# CY8C4247LQI_BL483 register map
File version: 0.1
PSoC 4200 BLE
Registers are 8-bit, read-write, no defined reset value unless marked. A register's access mark holds for its fields unless they carry their own. Offsets are from the block's base; lines under a group give offsets from that group; [hi:lo] are bit positions; {n}, {i} and the like mark numbered series; 'fields as' and 'values as' point back to an identical list; <NAME> marks a mode.

## Memory map
0x00000000 PWM
0x400F0072 front_motor
0x400F0073 rear_motor

## PWM
Base 0x00000000
0x400F0021 PWM__COMPARE1 — UDB.D0 - Assigned Compare1 Value
0x400F0031 PWM__COMPARE2 — UDB.D1 - Assigned Compare2 Value
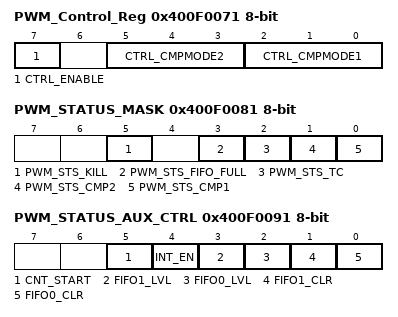
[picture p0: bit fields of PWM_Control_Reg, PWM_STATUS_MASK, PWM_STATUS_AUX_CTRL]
0x400F0071 PWM_Control_Reg — UDB Control Register - Assigned Control Register Value
  [7] CTRL_ENABLE — Enable the PWM
  [5:3] CTRL_CMPMODE2 — Compare mode 2
  [2:0] CTRL_CMPMODE1 — Compare mode 1
0x400F0081 PWM_STATUS_MASK — UDB Status bits Interrupt Mask Enable Register
  [5] PWM_STS_KILL ro — Enables the Interrupt on Kill
  [3] PWM_STS_FIFO_FULL ro — FIFO Full Status Mask
  [2] PWM_STS_TC ro — Enables the Interrupt on Terminal Count
  [1] PWM_STS_CMP2 ro — Enables the Interrupt on Compare 2
  [0] PWM_STS_CMP1 ro — Enables the Interrupt on Compare 1
0x400F0091 PWM_STATUS_AUX_CTRL — UDB Auxilliary Control Register
  [5] CNT_START — FIFO0 clear
    0=E_CNT_START0 (Disable counter); 1=E_CNT_START1 (Enable counter)
  [4] INT_EN
    0=E_INT_EN0 (Interrupt disabled); 1=E_INT_EN1 (Interrupt enabled)
  [3] FIFO1_LVL — FIFO level
    0=E_FIFO_LVL_0 (FIFO LVL: input mode: FIFO not full; output mode: FIFO not empty); 1=E_FIFO_LVL_1 (FIFO LVL: input mode: FIFO at least 1/2 empty; output mode: FIFO at least 1/2 full)
  [2] FIFO0_LVL — FIFO level
    values as FIFO1_LVL
  [1] FIFO1_CLR — FIFO1 clear
    0=E_FIFO_CLR_0 (Normal FIFO operation); 1=E_FIFO_CLR_1 (Clear FIFO state)
  [0] FIFO0_CLR — FIFO0 clear
    values as FIFO1_CLR

## front_motor
Base 0x400F0072
0x00 front_motor_CONTROL_REG

## rear_motor
Base 0x400F0073
Registers as front_motor (with front_motor read as rear_motor).
